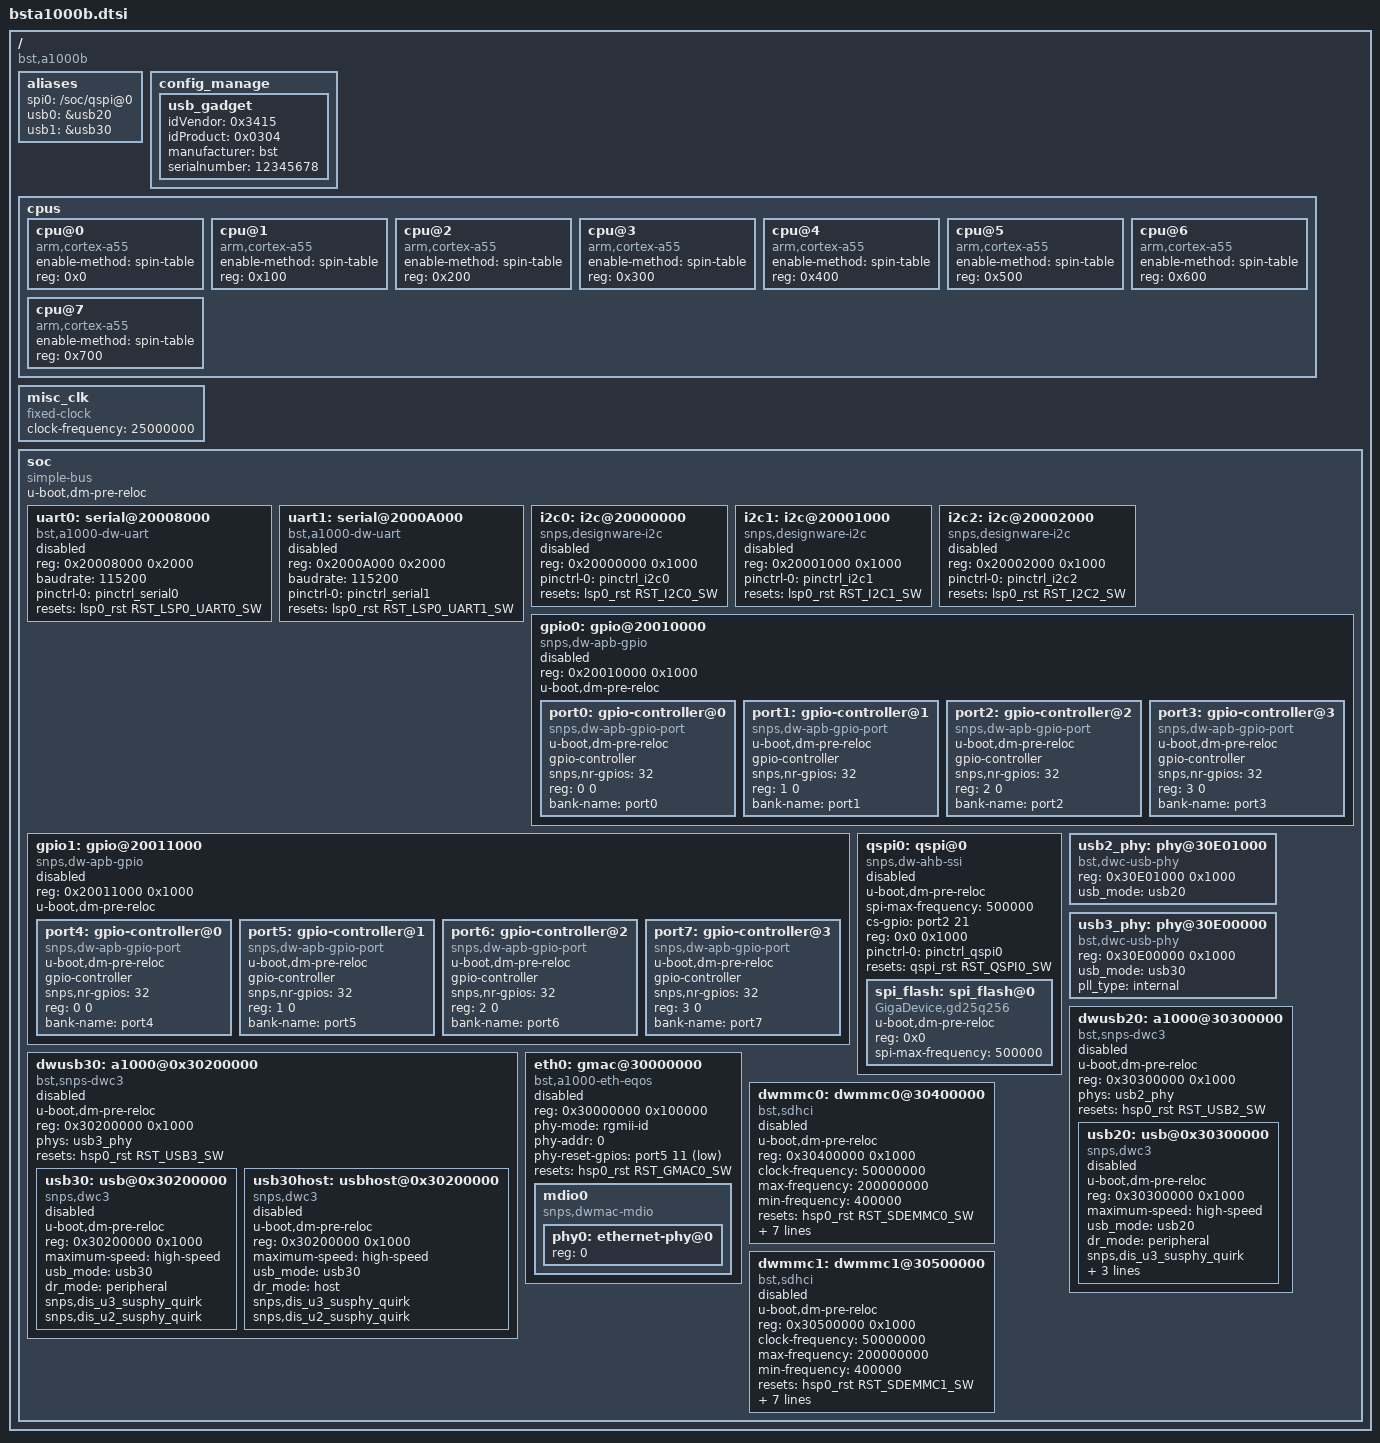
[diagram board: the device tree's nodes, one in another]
// SPDX-License-Identifier: GPL-2.0
#include "bsta1000b-pinctrl.dtsi"
#include "bsta1000b-reset.dtsi"

/ {
	compatible = "bst,a1000b";
	#address-cells = <2>;
	#size-cells = <2>;

	aliases {
		spi0 = "/soc/qspi@0";
		usb0 = &usb20;
		usb1 = &usb30;
	};
	config_manage {
		usb_gadget {
			idVendor = <0x3415>;
			idProduct = <0x0304>;
			manufacturer = "bst";
			serialnumber = "12345678";
		};
	};
	cpus {
		#address-cells = <0x1>;
		#size-cells = <0x0>;

		cpu@0 {
			compatible = "arm,cortex-a55", "arm,armv8";
			device_type = "cpu";
			enable-method = "spin-table";
			reg = <0x0>;
		};

		cpu@1 {
			compatible = "arm,cortex-a55", "arm,armv8";
			device_type = "cpu";
			enable-method = "spin-table";
			reg = <0x100>;
		};

		cpu@2 {
			compatible = "arm,cortex-a55", "arm,armv8";
			device_type = "cpu";
			enable-method = "spin-table";
			reg = <0x200>;
		};

		cpu@3 {
			compatible = "arm,cortex-a55", "arm,armv8";
			device_type = "cpu";
			enable-method = "spin-table";
			reg = <0x300>;
		};

		cpu@4 {
			compatible = "arm,cortex-a55", "arm,armv8";
			device_type = "cpu";
			enable-method = "spin-table";
			reg = <0x400>;
		};


		cpu@5 {
			compatible = "arm,cortex-a55", "arm,armv8";
			device_type = "cpu";
			enable-method = "spin-table";
			reg = <0x500>;
		};

		cpu@6 {
			compatible = "arm,cortex-a55", "arm,armv8";
			device_type = "cpu";
			enable-method = "spin-table";
			reg = <0x600>;
		};

		cpu@7 {
			compatible = "arm,cortex-a55", "arm,armv8";
			device_type = "cpu";
			enable-method = "spin-table";
			reg = <0x700>;
		};

	};

	misc_clk {
		compatible = "fixed-clock";
		#clock-cells = <0x0>;
		clock-frequency = <25000000>;
	};

	soc {
		#address-cells = <1>;
		#size-cells = <1>;
		compatible = "simple-bus";
		device_type = "soc";
		u-boot,dm-pre-reloc;

		uart0: serial@20008000 {
			compatible = "bst,a1000-dw-uart";
			#address-cells = <1>;
			#size-cells = <1>;
			reg = <0x20008000 0x2000>;
			baudrate = <115200>;
			pinctrl-names = "default";
			pinctrl-0 = <&pinctrl_serial0>;
			resets = <&lsp0_rst RST_LSP0_UART0_SW>;
			status = "disable";
		};

		uart1: serial@2000A000 {
			compatible = "bst,a1000-dw-uart";
			#address-cells = <1>;
			#size-cells = <1>;
			reg = <0x2000A000 0x2000>;
			baudrate = <115200>;
			pinctrl-names = "default";
			pinctrl-0 = <&pinctrl_serial1>;
			resets = <&lsp0_rst RST_LSP0_UART1_SW>;
			status = "disable";
		};

		i2c0: i2c@20000000 {
			compatible = "snps,designware-i2c";
			#address-cells = <1>;
			#size-cells = <1>;
			reg = <0x20000000 0x1000>;
			pinctrl-names = "default";
			pinctrl-0 = <&pinctrl_i2c0>;
			reset-names = "i2c";
			resets = <&lsp0_rst RST_I2C0_SW>;
			status = "disable";
		};

		i2c1: i2c@20001000 {
			compatible = "snps,designware-i2c";
			#address-cells = <1>;
			#size-cells = <1>;
			reg = <0x20001000 0x1000>;
			pinctrl-names = "default";
			pinctrl-0 = <&pinctrl_i2c1>;
			reset-names = "i2c";
			resets = <&lsp0_rst RST_I2C1_SW>;
			status = "disable";
		};

		i2c2: i2c@20002000 {
			compatible = "snps,designware-i2c";
			#address-cells = <1>;
			#size-cells = <1>;
			reg = <0x20002000 0x1000>;
			pinctrl-names = "default";
			pinctrl-0 = <&pinctrl_i2c2>;
			reset-names = "i2c";
			resets = <&lsp0_rst RST_I2C2_SW>;
			status = "disable";
		};

		gpio0: gpio@20010000 {
			#address-cells = <1>;
			#size-cells = <0>;
			compatible = "snps,dw-apb-gpio";
			reg = <0x20010000 0x1000>;
			status = "disable";
			u-boot,dm-pre-reloc;

			port0: gpio-controller@0 {
				compatible = "snps,dw-apb-gpio-port";
				u-boot,dm-pre-reloc;
				gpio-controller;
				#gpio-cells = <2>;
				snps,nr-gpios = <32>;
				reg = <0 0>;
				bank-name = "port0";
			};

			port1: gpio-controller@1 {
				compatible = "snps,dw-apb-gpio-port";
				u-boot,dm-pre-reloc;
				gpio-controller;
				#gpio-cells = <2>;
				snps,nr-gpios = <32>;
				reg = <1 0>;
				bank-name = "port1";
			};

			port2: gpio-controller@2 {
				compatible = "snps,dw-apb-gpio-port";
				u-boot,dm-pre-reloc;
				gpio-controller;
				#gpio-cells = <2>;
				snps,nr-gpios = <32>;
				reg = <2 0>;
				bank-name = "port2";
			};
			port3: gpio-controller@3 {
				compatible = "snps,dw-apb-gpio-port";
				u-boot,dm-pre-reloc;
				gpio-controller;
				#gpio-cells = <2>;
				snps,nr-gpios = <32>;
				reg = <3 0>;
				bank-name = "port3";
			};
		};

		gpio1: gpio@20011000 {
			#address-cells = <1>;
			#size-cells = <0>;
			compatible = "snps,dw-apb-gpio";
			reg = <0x20011000 0x1000>;
			status = "disable";
			u-boot,dm-pre-reloc;

			port4: gpio-controller@0 {
				compatible = "snps,dw-apb-gpio-port";
				u-boot,dm-pre-reloc;
				gpio-controller;
				#gpio-cells = <2>;
				snps,nr-gpios = <32>;
				reg = <0 0>;
				bank-name = "port4";
			};

			port5: gpio-controller@1 {
				compatible = "snps,dw-apb-gpio-port";
				u-boot,dm-pre-reloc;
				gpio-controller;
				#gpio-cells = <2>;
				snps,nr-gpios = <32>;
				reg = <1 0>;
				bank-name = "port5";
			};

			port6: gpio-controller@2 {
				compatible = "snps,dw-apb-gpio-port";
				u-boot,dm-pre-reloc;
				gpio-controller;
				#gpio-cells = <2>;
				snps,nr-gpios = <32>;
				reg = <2 0>;
				bank-name = "port6";
			};
			port7: gpio-controller@3 {
				compatible = "snps,dw-apb-gpio-port";
				u-boot,dm-pre-reloc;
				gpio-controller;
				#gpio-cells = <2>;
				snps,nr-gpios = <32>;
				reg = <3 0>;
				bank-name = "port7";
			};
		};

		qspi0: qspi@0 {
			#address-cells = <1>;
			#size-cells = <0>;
			status = "disable";
			compatible = "snps,dw-ahb-ssi";
			u-boot,dm-pre-reloc;
			spi-max-frequency = <500000>;
			cs-gpio = <&port2 21 0>;//GPIO85
			reg = <0x0 0x1000>;
			pinctrl-names = "default";
			pinctrl-0 = <&pinctrl_qspi0>;
			resets = <&qspi_rst RST_QSPI0_SW>;
			spi_flash: spi_flash@0 {
				#address-cells = <1>;
				#size-cells = <1>;
				compatible = "GigaDevice,gd25q256",
					    "jedec,spi-nor";
				u-boot,dm-pre-reloc;
				reg = <0x0>;/* CS0 */
				spi-max-frequency = <500000>;
			};
		};
		usb2_phy: phy@30E01000 {
			compatible = "bst,dwc-usb-phy";
			#phy-cells = <0>;
			reg = <0x30E01000 0x1000>;
			usb_mode = "usb20";
		};
		usb3_phy: phy@30E00000 {
			compatible = "bst,dwc-usb-phy";
			reg = <0x30E00000 0x1000>;
			#phy-cells = <0>;
			usb_mode = "usb30";
			pll_type = "internal";
		};
		dwusb20: a1000@30300000 {
			#address-cells = <1>;
			#size-cells = <1>;
			status = "disable";
			compatible = "bst,snps-dwc3";
			u-boot,dm-pre-reloc;
			reg = <0x30300000 0x1000>;
			ranges;
			phys = <&usb2_phy>;
			phy-names = "usb3-phy";
			reset-names = "usb2";
			resets = <&hsp0_rst RST_USB2_SW>;
			usb20:usb@0x30300000 {
				compatible = "snps,dwc3";
				u-boot,dm-pre-reloc;
				reg = <0x30300000 0x1000>;
				status = "disable";
				maximum-speed = "high-speed";
				usb_mode = "usb20";
				dr_mode = "peripheral";
				snps,dis_u3_susphy_quirk;
				snps,dis_u2_susphy_quirk;
				snps,reqinfo-for-data-read = <8>;
				snps,reqinfo-for-descriptor-read = <8>;
			};
		};

		dwusb30: a1000@0x30200000 {
			#address-cells = <1>;
			#size-cells = <1>;
			status = "disable";
			compatible = "bst,snps-dwc3";
			u-boot,dm-pre-reloc;
			reg = <0x30200000 0x1000>;
			ranges;
			phys = <&usb3_phy>;
			phy-names = "usb3-phy";
			reset-names = "usb3";
			resets = <&hsp0_rst RST_USB3_SW>;
			usb30:usb@0x30200000 {
				compatible = "snps,dwc3";
				u-boot,dm-pre-reloc;
				reg = <0x30200000 0x1000>;
				status = "disable";
				maximum-speed = "high-speed";
				usb_mode = "usb30";
				dr_mode = "peripheral";
				snps,dis_u3_susphy_quirk;
				snps,dis_u2_susphy_quirk;
			};
			usb30host:usbhost@0x30200000 {
				compatible = "snps,dwc3";
				u-boot,dm-pre-reloc;
				reg = <0x30200000 0x1000>;
				status = "disable";
				maximum-speed = "high-speed";
				usb_mode = "usb30";
				dr_mode = "host";
				snps,dis_u3_susphy_quirk;
				snps,dis_u2_susphy_quirk;
			};
		};

		eth0: gmac@30000000 {
			reg = <0x30000000 0x100000>;
			#address-cells = <1>;
			#size-cells = <0>;
			compatible = "bst,a1000-eth-eqos";
			phy-mode = "rgmii-id";
			phy-addr = < 0 >;
			phy-reset-gpios = <&port5 11 1>;//GPIO 171
			status = "disable";
			resets = <&hsp0_rst RST_GMAC0_SW>;
			mdio0 {
				#address-cells = <1>;
				#size-cells = <0>;
				compatible = "snps,dwmac-mdio";
				phy0: ethernet-phy@0 {
					reg = <0>;
				};
			};
		};


		dwmmc0: dwmmc0@30400000 {
			compatible = "bst,sdhci";
			u-boot,dm-pre-reloc;
			reg = <0x30400000 0x1000>;
			clock-frequency = <50000000>;
			max-frequency = <200000000>;
			min-frequency = <400000>;
			resets = <&hsp0_rst RST_SDEMMC0_SW>;
			bus-width = <8>;
			status = "disable";
			//card-detect-delay = <200>;
			cap-mmc-highspeed;
			non-removable;
			no-sdio;
			no-sd;
			keep-power-in-suspend;
			no-3-3-v;
		};
		dwmmc1: dwmmc1@30500000 {
			compatible = "bst,sdhci";
			u-boot,dm-pre-reloc;
			reg = <0x30500000 0x1000>;
			clock-frequency = <50000000>;
			max-frequency = <200000000>;
			min-frequency = <400000>;
			resets = <&hsp0_rst RST_SDEMMC1_SW>;
			bus-width = <4>;
			status = "disable";
			//card-detect-delay = <200>;
			cap-sd-highspeed;
			no-sdio;
			no-mmc;
			keep-power-in-suspend;
			no-1-8-v;
			mmc-ddr-3_3v;
		};
	};
};
